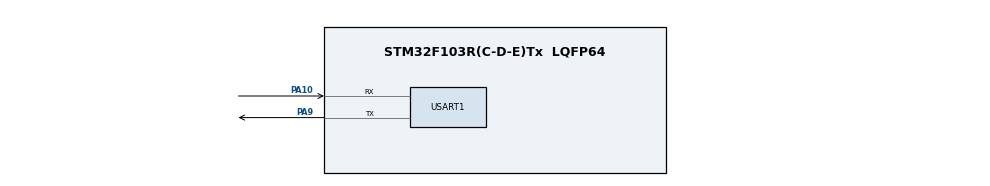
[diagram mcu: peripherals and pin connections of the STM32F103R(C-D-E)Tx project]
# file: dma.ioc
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Dma.Request0=USART1_RX
Dma.USART1_RX.0.Direction=DMA_PERIPH_TO_MEMORY
Dma.USART1_RX.0.Instance=DMA1_Channel5
Dma.USART1_RX.0.MemDataAlignment=DMA_MDATAALIGN_BYTE
Dma.USART1_RX.0.MemInc=DMA_MINC_ENABLE
Dma.USART1_RX.0.Mode=DMA_NORMAL
Dma.USART1_RX.0.PeriphDataAlignment=DMA_PDATAALIGN_BYTE
Dma.USART1_RX.0.PeriphInc=DMA_PINC_DISABLE
Dma.USART1_RX.0.Priority=DMA_PRIORITY_LOW
Mcu.Family=STM32F1
Mcu.Name=STM32F103R(C-D-E)Tx
Mcu.Package=LQFP64
NVIC.DMA1_Channel5_IRQn=true\:0\:0\:false\:false\:true\:false\:true\:true
NVIC.PriorityGroup=NVIC_PRIORITYGROUP_4
NVIC.USART1_IRQn=true\:0\:0\:false\:false\:true\:true\:true\:true
PA10.Mode=Asynchronous
PA10.Signal=USART1_RX
PA9.Mode=Asynchronous
PA9.Signal=USART1_TX
ProjectManager.HeapSize=0x200
ProjectManager.StackSize=0x400
ProjectManager.TargetToolchain=MDK-ARM V5.32
RCC.APB1Freq_Value=8000000
RCC.APB2Freq_Value=8000000
USART1.VirtualMode=VM_ASYNC
VP_SYS_VS_ND.Mode=No_Debug
board=custom

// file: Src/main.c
/* USER CODE BEGIN Header */
/**
  ******************************************************************************
  * @file           : main.c
  * @brief          : Main program body
  ******************************************************************************
  * @attention
  *
  * Copyright (c) 2022 STMicroelectronics.
  * All rights reserved.
  *
  * This software is licensed under terms that can be found in the LICENSE file
  * in the root directory of this software component.
  * If no LICENSE file comes with this software, it is provided AS-IS.
  *不定长数据接收任务
	*stm32f1xx_it.c与main.c共同使用全局变量，RxFlag,一般在中断中使用的全局变量都要使用volatile修饰
  ******************************************************************************
  */
/* USER CODE END Header */
#include "main.h"
#include <stdio.h>

/* USER CODE BEGIN PD */
#define LENGTH 100  //数据缓冲区大小，一定要大于一帧数据的总字符数
/* USER CODE END PD */

UART_HandleTypeDef huart1;
DMA_HandleTypeDef hdma_usart1_rx; //Mx软件生成的DMA数据流句柄

/* USER CODE BEGIN PV */
uint8_t RxBuffer[LENGTH];//数据缓冲区
uint8_t RxCount=0;//实际接收的数据项数
volatile uint8_t RxFlag=0;//数据接收标志，0表示未接收完成
/* USER CODE END PV */

void SystemClock_Config(void);
static void MX_GPIO_Init(void);
static void MX_DMA_Init(void);
static void MX_USART1_UART_Init(void);

int main(void)
{

  /* MCU Configuration--------------------------------------------------------*/

  /* Reset of all peripherals, Initializes the Flash interface and the Systick. */
  HAL_Init();

  /* Configure the system clock */
  SystemClock_Config();

  /* Initialize all configured peripherals */
  MX_GPIO_Init();
  MX_DMA_Init();
  MX_USART1_UART_Init();
  /* USER CODE BEGIN 2 */
//发送提示信息
printf("*********** UART communcation QQ using IDLE IT+DMA *******\n");
printf("Please enter arbitrary length characters:\n");
__HAL_UART_ENABLE_IT(&huart1,UART_IT_IDLE);//使能IDLE中断
HAL_UART_Receive_DMA(&huart1,(uint8_t*)RxBuffer,LENGTH);//启动DMA接收
  /* USER CODE END 2 */

  /* Infinite loop */
  while (1)
  {
		if(RxFlag){//判断是否接收完成
			RxFlag=0;
			HAL_UART_DMAStop(&huart1);//停止串口DMA传输
			//发生空闲中断时，已接收数据的项数等于数据总量剪去DMA数据流中剩余未接收的数据项
			RxCount =LENGTH-__HAL_DMA_GET_COUNTER(&hdma_usart1_rx);
			//采用轮询方式将数据原样传回pc
			HAL_UART_Transmit(&huart1,(uint8_t*)RxBuffer,RxCount,100);
			for(uint8_t i=0;i<RxCount;i++){
				RxBuffer[i]=0;
			}
			RxCount=0;
			//重启DMA
			HAL_UART_Receive_DMA(&huart1,(uint8_t*)RxBuffer,LENGTH);

		}

  }
}

void SystemClock_Config(void)
{
  RCC_OscInitTypeDef RCC_OscInitStruct = {0};
  RCC_ClkInitTypeDef RCC_ClkInitStruct = {0};

  /** Initializes the RCC Oscillators according to the specified parameters
  * in the RCC_OscInitTypeDef structure.
  */
  RCC_OscInitStruct.OscillatorType = RCC_OSCILLATORTYPE_HSI;
  RCC_OscInitStruct.HSIState = RCC_HSI_ON;
  RCC_OscInitStruct.HSICalibrationValue = RCC_HSICALIBRATION_DEFAULT;
  RCC_OscInitStruct.PLL.PLLState = RCC_PLL_NONE;
  if (HAL_RCC_OscConfig(&RCC_OscInitStruct) != HAL_OK)
  {
    Error_Handler();
  }

  /** Initializes the CPU, AHB and APB buses clocks
  */
  RCC_ClkInitStruct.ClockType = RCC_CLOCKTYPE_HCLK|RCC_CLOCKTYPE_SYSCLK
                              |RCC_CLOCKTYPE_PCLK1|RCC_CLOCKTYPE_PCLK2;
  RCC_ClkInitStruct.SYSCLKSource = RCC_SYSCLKSOURCE_HSI;
  RCC_ClkInitStruct.AHBCLKDivider = RCC_SYSCLK_DIV1;
  RCC_ClkInitStruct.APB1CLKDivider = RCC_HCLK_DIV1;
  RCC_ClkInitStruct.APB2CLKDivider = RCC_HCLK_DIV1;

  if (HAL_RCC_ClockConfig(&RCC_ClkInitStruct, FLASH_LATENCY_0) != HAL_OK)
  {
    Error_Handler();
  }
}

static void MX_USART1_UART_Init(void)
{

  huart1.Instance = USART1;
  huart1.Init.BaudRate = 115200;
  huart1.Init.WordLength = UART_WORDLENGTH_8B;
  huart1.Init.StopBits = UART_STOPBITS_1;
  huart1.Init.Parity = UART_PARITY_NONE;
  huart1.Init.Mode = UART_MODE_TX_RX;
  huart1.Init.HwFlowCtl = UART_HWCONTROL_NONE;
  huart1.Init.OverSampling = UART_OVERSAMPLING_16;
  if (HAL_UART_Init(&huart1) != HAL_OK)
  {
    Error_Handler();
  }

}

static void MX_DMA_Init(void)
{

  /* DMA controller clock enable */
  __HAL_RCC_DMA1_CLK_ENABLE();

  /* DMA interrupt init */
  /* DMA1_Channel5_IRQn interrupt configuration */
  HAL_NVIC_SetPriority(DMA1_Channel5_IRQn, 0, 0);
  HAL_NVIC_EnableIRQ(DMA1_Channel5_IRQn);

}

static void MX_GPIO_Init(void)
{

  /* GPIO Ports Clock Enable */
  __HAL_RCC_GPIOA_CLK_ENABLE();

}

/* USER CODE BEGIN 4 */
//串口重定向函数
int fputc(int ch,FILE *f){
	//采用轮询方式发送1字节数据，超时时间设置为无限等待
	HAL_UART_Transmit(&huart1,(uint8_t*)&ch,1,HAL_MAX_DELAY);
	return ch;
}
int fgetc(FILE*f){
	uint8_t ch;
		//采用轮询方式发送1字节数据，超时时间设置为无限等待
	HAL_UART_Receive(&huart1,(uint8_t*)&ch,1,HAL_MAX_DELAY);
	return ch;

}

/* USER CODE END 4 */

void Error_Handler(void)
{
  __disable_irq();
  while (1)
  {
  }
}
